# STM32MP13xx register map
File version: 1.5
CPU: CA7 r0p0, little endian, MPU, FPU, 4 interrupt priority bits
Registers are 32-bit, read-write, reset 0x0 unless marked. A register's access mark holds for its fields unless they carry their own. Offsets are from the block's base; [hi:lo] are bit positions; {n}, {i} and the like mark numbered series; 'fields as' and 'values as' point back to an identical list.

## TAMP
Base 0x5C00A000
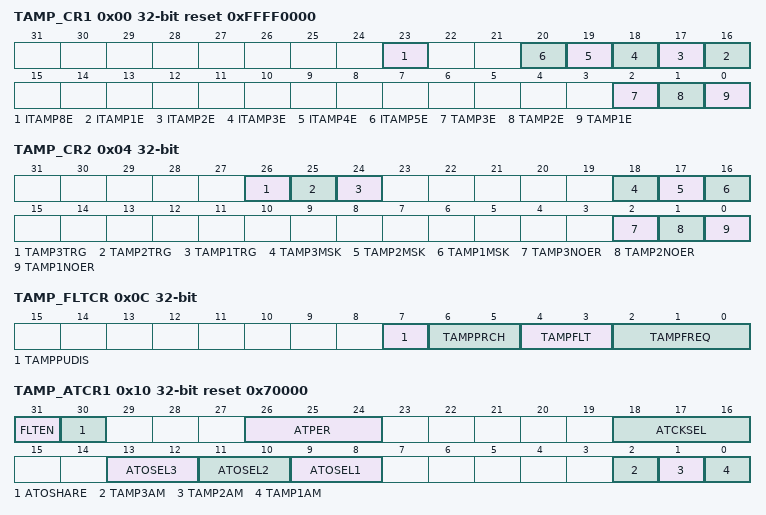
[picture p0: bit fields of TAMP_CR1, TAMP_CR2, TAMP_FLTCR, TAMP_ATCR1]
0x00 TAMP_CR1 reset 0xFFFF0000 — This register can be protected against non-secure access. Refer to Section51.3.3: TAMP secure protection modes.
  [23] ITAMP8E, [n+15] ITAMP{n}E (n=1..5), [2] TAMP3E, [1] TAMP2E, [0] TAMP1E
0x04 TAMP_CR2 — This register can be protected against non-secure access. Refer to Section51.3.3: TAMP secure protection modes.
  [26] TAMP3TRG, [25] TAMP2TRG, [24] TAMP1TRG, [18] TAMP3MSK, [17] TAMP2MSK, [16] TAMP1MSK, [2] TAMP3NOER, [1] TAMP2NOER, [0] TAMP1NOER
0x0C TAMP_FLTCR — This register can be protected against non-secure access. Refer to Section51.3.3: TAMP secure protection modes.
  [7] TAMPPUDIS, [6:5] TAMPPRCH, [4:3] TAMPFLT, [2:0] TAMPFREQ
0x10 TAMP_ATCR1 reset 0x70000 — This register can be protected against non-secure access. Refer to Section51.3.3: TAMP secure protection modes.
  [31] FLTEN, [30] ATOSHARE, [26:24] ATPER, [18:16] ATCKSEL, [13:12] ATOSEL3, [11:10] ATOSEL2, [9:8] ATOSEL1, [2] TAMP3AM, [1] TAMP2AM, [0] TAMP1AM
0x14 TAMP_ATSEEDR wo — This register can be protected against non-secure access. Refer to Section51.3.3: TAMP secure protection modes.
  [31:0] SEED
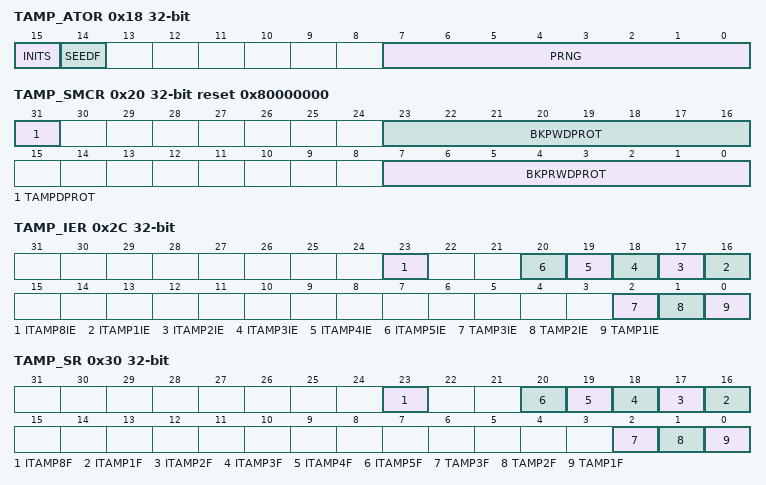
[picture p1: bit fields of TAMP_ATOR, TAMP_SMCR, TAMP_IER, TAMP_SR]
0x18 TAMP_ATOR ro — This register can be protected against non-secure access. Refer to Section51.3.3: TAMP secure protection modes.
  [15] INITS, [14] SEEDF, [7:0] PRNG
0x20 TAMP_SMCR reset 0x80000000 — This register can be written only when the APB access is secure.
  [31] TAMPDPROT, [23:16] BKPWDPROT, [7:0] BKPRWDPROT
0x2C TAMP_IER — This register can be protected against non-secure access. Refer to Section51.3.3: TAMP secure protection modes.
  [23] ITAMP8IE, [n+15] ITAMP{n}IE (n=1..5), [2] TAMP3IE, [1] TAMP2IE, [0] TAMP1IE
0x30 TAMP_SR ro — This register can be protected against non-secure access. Refer to Section51.3.3: TAMP secure protection modes.
  [23] ITAMP8F, [n+15] ITAMP{n}F (n=1..5), [2] TAMP3F, [1] TAMP2F, [0] TAMP1F
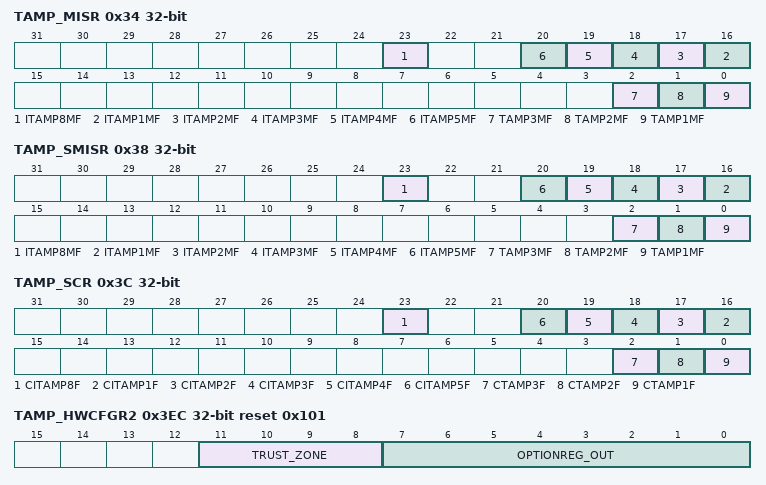
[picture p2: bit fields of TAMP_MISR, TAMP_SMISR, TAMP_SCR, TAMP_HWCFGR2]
0x34 TAMP_MISR ro — TAMP non-secure masked interrupt status register
  [23] ITAMP8MF, [n+15] ITAMP{n}MF (n=1..5), [2] TAMP3MF, [1] TAMP2MF, [0] TAMP1MF
0x38 TAMP_SMISR ro — TAMP secure masked interrupt status register
  fields as TAMP_MISR
0x3C TAMP_SCR wo — TAMP status clear register
  [23] CITAMP8F, [n+15] CITAMP{n}F (n=1..5), [2] CTAMP3F, [1] CTAMP2F, [0] CTAMP1F
0x40 TAMP_COUNTR ro — TAMP monotonic counter register
  [31:0] COUNT
0x50 TAMP_CFGR — TAMP configuration register
  [0] OUT3_RMP
{0x100+4i} TAMP_BKP{i}R (i=0..31) — TAMP backup {i} register
  [31:0] BKP
0x3EC TAMP_HWCFGR2 ro reset 0x101 — TAMP hardware configuration register 2
  [11:8] TRUST_ZONE, [7:0] OPTIONREG_OUT
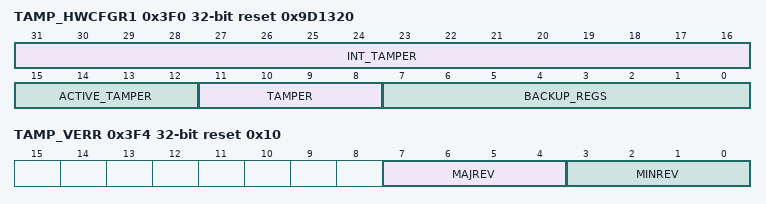
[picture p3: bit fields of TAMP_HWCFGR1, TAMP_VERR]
0x3F0 TAMP_HWCFGR1 ro reset 0x9D1320 — TAMP hardware configuration register 1
  [31:16] INT_TAMPER, [15:12] ACTIVE_TAMPER, [11:8] TAMPER, [7:0] BACKUP_REGS
0x3F4 TAMP_VERR ro reset 0x10 — TAMP version register
  [7:4] MAJREV, [3:0] MINREV
0x3F8 TAMP_IPIDR ro reset 0x121033 — TAMP identification register
  [31:0] ID
0x3FC TAMP_SIDR ro reset 0xA3C5DD01 — TAMP size identification register
  [31:0] SID

## TIM6
Base 0x40004000
Same registers: TIM7 0x40005000
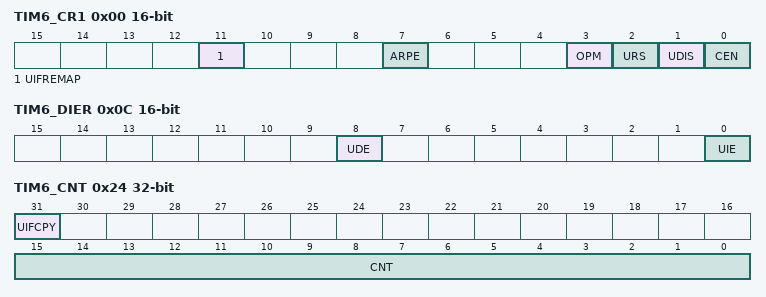
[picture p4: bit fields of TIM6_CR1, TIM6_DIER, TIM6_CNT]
0x00 TIM6_CR1 16-bit — TIM6 control register 1
  [11] UIFREMAP, [7] ARPE, [3] OPM, [2] URS, [1] UDIS, [0] CEN
0x04 TIM6_CR2 — TIM6 control register 2
  [6:4] MMS
0x0C TIM6_DIER 16-bit — TIM6 DMA/interrupt enable register
  [8] UDE, [0] UIE
0x10 TIM6_SR — TIM6 status register
  [0] UIF
0x14 TIM6_EGR 16-bit wo — TIM6 event generation register
  [0] UG
0x24 TIM6_CNT access per field — TIM6 counter
  [31] UIFCPY ro, [15:0] CNT rw
0x28 TIM6_PSC 16-bit — TIM6 prescaler
0x2C TIM6_ARR 16-bit reset 0xFFFF — TIM6 auto-reload register

## TIM15
Base 0x4C00A000
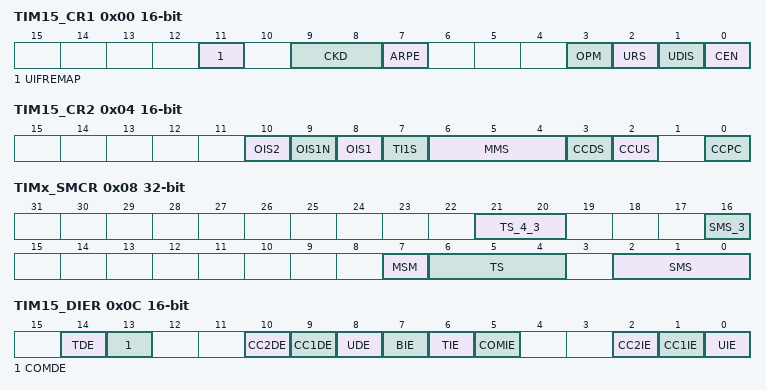
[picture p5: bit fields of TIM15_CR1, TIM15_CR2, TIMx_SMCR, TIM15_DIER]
0x00 TIM15_CR1 16-bit — TIM15 control register 1
  [11] UIFREMAP, [9:8] CKD, [7] ARPE, [3] OPM, [2] URS, [1] UDIS, [0] CEN
0x04 TIM15_CR2 16-bit — TIM15 control register 2
  [10] OIS2, [9] OIS1N, [8] OIS1, [7] TI1S, [6:4] MMS, [3] CCDS, [2] CCUS, [0] CCPC
0x08 TIMx_SMCR — slave mode control register
  [21:20] TS_4_3 — Trigger selection
  [16] SMS_3 — Slave mode selection - bit 3
  [7] MSM — Master/Slave mode
  [6:4] TS — Trigger selection
  [2:0] SMS — Slave mode selection
0x0C TIM15_DIER 16-bit — TIM15 DMA/interrupt enable register
  [14] TDE, [13] COMDE, [10] CC2DE, [9] CC1DE, [8] UDE, [7] BIE, [6] TIE, [5] COMIE, [2] CC2IE, [1] CC1IE, [0] UIE
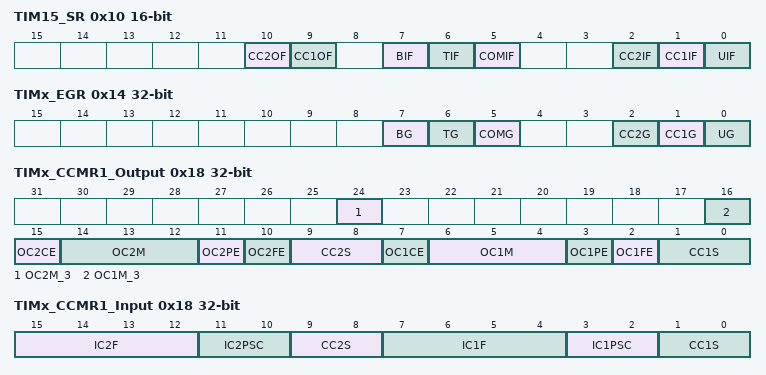
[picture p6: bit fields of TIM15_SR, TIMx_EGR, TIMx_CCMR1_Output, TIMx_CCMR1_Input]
0x10 TIM15_SR 16-bit — TIM15 status register
  [10] CC2OF, [9] CC1OF, [7] BIF, [6] TIF, [5] COMIF, [2] CC2IF, [1] CC1IF, [0] UIF
0x14 TIMx_EGR wo — event generation register
  [7] BG
  [6] TG — Trigger generation
  [5] COMG
  [2] CC2G — Capture/compare 2 generation
  [1] CC1G — Capture/compare 1 generation
  [0] UG — Update generation
0x18 TIMx_CCMR1_Output — capture/compare mode register 1 (output mode)
  [24] OC2M_3 — Output Compare 2 mode - bit 3
  [16] OC1M_3 — Output Compare 1 mode - bit 3
  [15] OC2CE — Output compare 2 clear enable
  [14:12] OC2M — Output compare 2 mode
  [11] OC2PE — Output compare 2 preload enable
  [10] OC2FE — Output compare 2 fast enable
  [9:8] CC2S — Capture/Compare 2 selection
  [7] OC1CE — Output compare 1 clear enable
  [6:4] OC1M — Output compare 1 mode
  [3] OC1PE — Output compare 1 preload enable
  [2] OC1FE — Output compare 1 fast enable
  [1:0] CC1S — Capture/Compare 1 selection
0x18 TIMx_CCMR1_Input (alternate view of TIMx_CCMR1_Output) — capture/compare mode register 1 (input mode)
  [15:12] IC2F — Input capture 2 filter
  [11:10] IC2PSC — Input capture 2 prescaler
  [9:8] CC2S — Capture/compare 2 selection
  [7:4] IC1F — Input capture 1 filter
  [3:2] IC1PSC — Input capture 1 prescaler
  [1:0] CC1S — Capture/Compare 1 selection
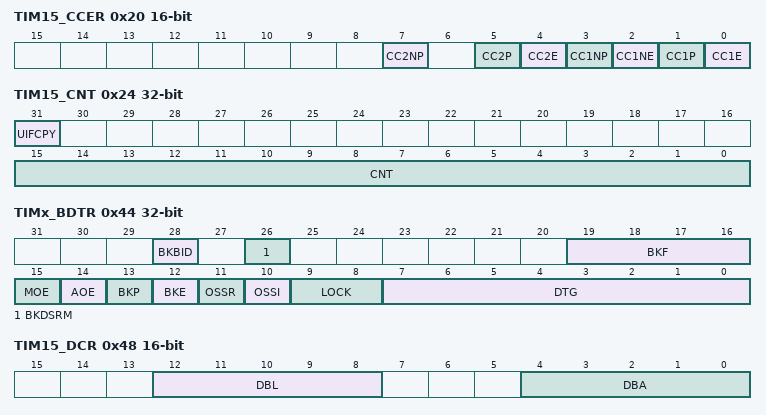
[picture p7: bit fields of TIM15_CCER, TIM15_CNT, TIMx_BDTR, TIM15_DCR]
0x20 TIM15_CCER 16-bit — TIM15 capture/compare enable register
  [7] CC2NP, [5] CC2P, [4] CC2E, [3] CC1NP, [2] CC1NE, [1] CC1P, [0] CC1E
0x24 TIM15_CNT — TIM15 counter
  [31] UIFCPY ro, [15:0] CNT
0x28 TIM15_PSC 16-bit — TIM15 prescaler
0x2C TIM15_ARR 16-bit reset 0xFFFF — TIM15 auto-reload register
0x30 TIM15_RCR 16-bit — TIM15 repetition counter register
  [7:0] REP
0x34 TIM15_CCR1 16-bit — TIM15 capture/compare register 1
0x38 TIM15_CCR2 16-bit — TIM15 capture/compare register 2
0x44 TIMx_BDTR — As the bits BK2BID, BKBID, BK2DSRM, BKDSRM, BK2P, BK2E, BK2F[3:0], BKF[3:0], AOE, BKP, BKE, OSSI, OSSR and DTG[7:0] can be write-locked depending on the LOCK configuration, it can be necessary to configure all of them during the first write access to the TIMx_BDTR register.
  [28] BKBID, [26] BKDSRM, [19:16] BKF, [15] MOE, [14] AOE, [13] BKP, [12] BKE, [11] OSSR, [10] OSSI, [9:8] LOCK, [7:0] DTG
0x48 TIM15_DCR 16-bit — TIM15 DMA control register
  [12:8] DBL, [4:0] DBA
0x4C TIM15_DMAR 16-bit — TIM15 DMA address for full transfer
  [15:0] DMAB
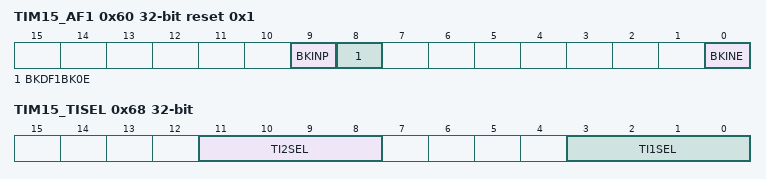
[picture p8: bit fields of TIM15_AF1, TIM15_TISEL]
0x60 TIM15_AF1 reset 0x1 — TIM15 alternate register 1
  [9] BKINP, [8] BKDF1BK0E, [0] BKINE
0x68 TIM15_TISEL — TIM15 input selection register
  [11:8] TI2SEL, [3:0] TI1SEL

## VREFBUF
Base 0x50025000
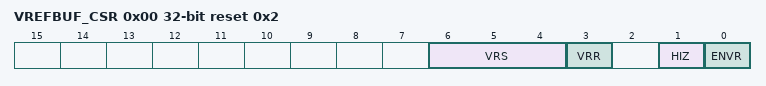
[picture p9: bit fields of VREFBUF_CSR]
0x00 VREFBUF_CSR access per field reset 0x2 — VREFBUF control and status register
  [6:4] VRS rw — Voltage reference scale These bits select the value generated by the voltage reference buffer. VRS = 000: VREFBUF0 voltage selected. VRS = 001: VREFBUF1 voltage selected. VRS = 010: VREFBUF2 voltage selected. VRS = 011: VREFBUF3 voltage selected. Others: Reserved Note: Refer to the product datasheet for each VREFBUFx voltage setting value. The software can program this bitfield only when the VREFBUF is disabled (ENVR=0).
  [3] VRR ro — Voltage reference buffer ready
    0=the voltage reference buffer output is not ready; 1=the voltage reference buffer output reached the requested level
  [1] HIZ rw — High impedance mode This bit controls the analog switch to connect or not the VREF+ pin. Refer to for the mode descriptions depending on ENVR bit configuration.
    0=VREF+ pin is internally connected to the voltage reference buffer output; 1=VREF+ pin is high impedance
  [0] ENVR rw — Voltage reference buffer mode enable This bit is used to enable the voltage reference buffer mode.
    0=Internal voltage reference mode disable (external voltage reference mode); 1=Internal voltage reference mode (reference buffer enable or hold mode) enable
0x04 VREFBUF_CCR (reset mask 0xFFFFFF00) — VREFBUF calibration control register
  [5:0] TRIM — Trimming code The TRIM code is a 6-bit unsigned data (minimum 000000, maximum 111111) that is set and updated according the mechanism described below. Reset: TRIM[5:0] is automatically initialized with the VRS = 0 trimming value stored in the Flash memory during the production test. VRS change: TRIM[5:0] is automatically initialized with the trimming value (corresponding to VRS setting) stored in the Flash memory during the production test. Write in TRIM[5:0]: User can modify the TRIM[5:0] with an arbitrary value. This is permanently disabling the control of the trimming value with VRS (until the device is reset). Note: If the user application performs the trimming, the trimming code must start from 000000 to 111111 in ascending order.
